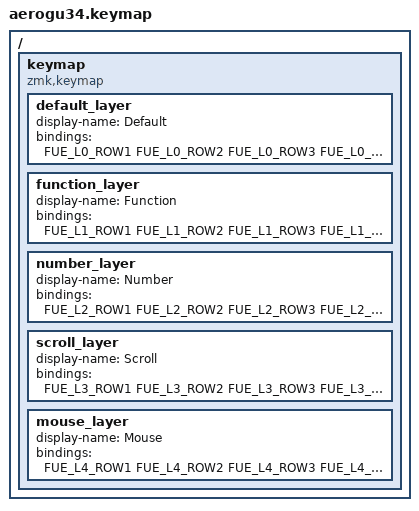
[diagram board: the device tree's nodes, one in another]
/*
 * aerogu34 キーマップ(ラッパー)
 *
 * ★実際のキー割り当ては共通リポジトリで定義★
 *   https://github.com/bakajaan/zmk-keymap-common
 *   include/fue/keymap34.dtsi
 * キーマップ変更は上記ファイルを編集すること。
 *
 * このファイルは共通34キー定義を自機のマトリクスへ展開するだけ。
 */

#define ZMK_POINTING_DEFAULT_SCRL_VAL 200

#include <dt-bindings/zmk/mouse.h>
#include <fue/keymap34.dtsi>

/ {
    keymap {
        compatible = "zmk,keymap";

        default_layer {
            display-name = "Default";
            bindings = <
FUE_L0_ROW1
FUE_L0_ROW2
FUE_L0_ROW3
FUE_L0_THUMBS
            >;
        };

        function_layer {
            display-name = "Function";
            bindings = <
FUE_L1_ROW1
FUE_L1_ROW2
FUE_L1_ROW3
FUE_L1_THUMBS
            >;
        };

        number_layer {
            display-name = "Number";
            bindings = <
FUE_L2_ROW1
FUE_L2_ROW2
FUE_L2_ROW3
FUE_L2_THUMBS
            >;
        };

        scroll_layer {
            display-name = "Scroll";
            bindings = <
FUE_L3_ROW1
FUE_L3_ROW2
FUE_L3_ROW3
FUE_L3_THUMBS
            >;
        };

        mouse_layer {
            display-name = "Mouse";
            bindings = <
FUE_L4_ROW1
FUE_L4_ROW2
FUE_L4_ROW3
FUE_L4_THUMBS
            >;
        };
    };
};
